AUTOSAR XML (schema 4-3-0)
standard types defined: Boolean, UInt8, SInt8, UInt16, SInt16, UInt32, SInt32, boolean, uint8, sint8, uint16, sint16, uint32, sint32
package /Components
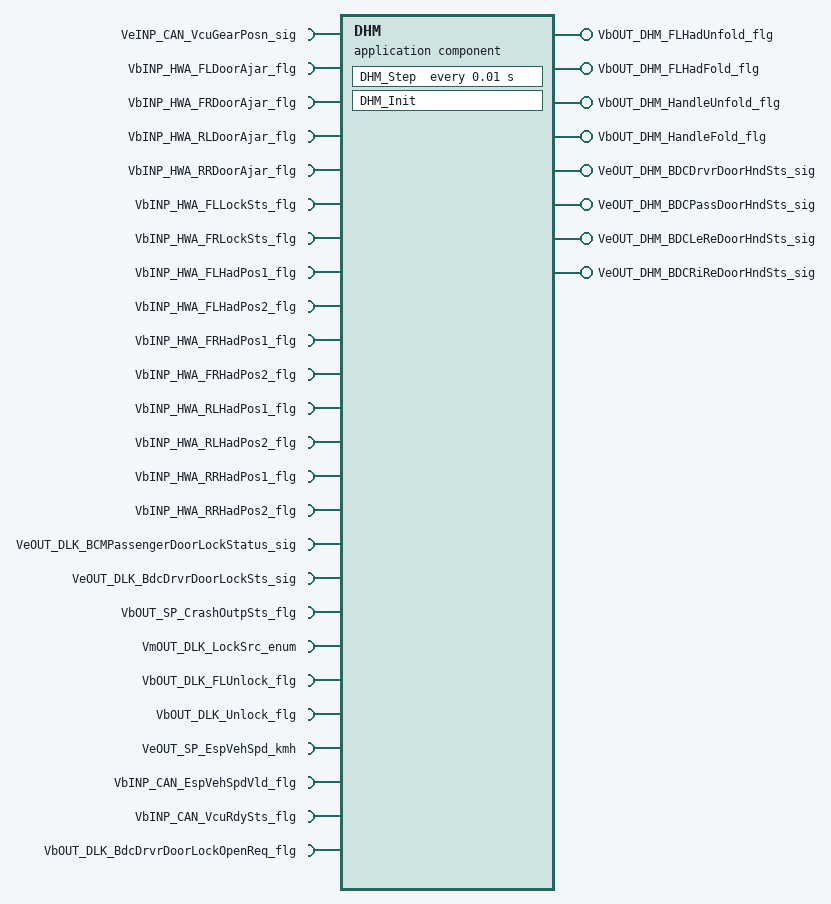
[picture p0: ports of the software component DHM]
  application sw component type DHM
    25 x require port:
      VeINP_CAN_VcuGearPosn_sig: nonqueued-receiver-com-spec{data-element=VeINP_CAN_VcuGearPosn_sig, init-value=0}, required-interface=VeINP_CAN_VcuGearPosn_sig
      VbINP_HWA_FLDoorAjar_flg: nonqueued-receiver-com-spec{data-element=VbINP_HWA_FLDoorAjar_flg, init-value=0}, required-interface=VbINP_HWA_FLDoorAjar_flg
      VbINP_HWA_FRDoorAjar_flg: nonqueued-receiver-com-spec{data-element=VbINP_HWA_FRDoorAjar_flg, init-value=0}, required-interface=VbINP_HWA_FRDoorAjar_flg
      VbINP_HWA_RLDoorAjar_flg: nonqueued-receiver-com-spec{data-element=VbINP_HWA_RLDoorAjar_flg, init-value=0}, required-interface=VbINP_HWA_RLDoorAjar_flg
      VbINP_HWA_RRDoorAjar_flg: nonqueued-receiver-com-spec{data-element=VbINP_HWA_RRDoorAjar_flg, init-value=0}, required-interface=VbINP_HWA_RRDoorAjar_flg
      VbINP_HWA_FLLockSts_flg: nonqueued-receiver-com-spec{data-element=VbINP_HWA_FLLockSts_flg, init-value=0}, required-interface=VbINP_HWA_FLLockSts_flg
      VbINP_HWA_FRLockSts_flg: nonqueued-receiver-com-spec{data-element=VbINP_HWA_FRLockSts_flg, init-value=0}, required-interface=VbINP_HWA_FRLockSts_flg
      VbINP_HWA_FLHadPos1_flg: nonqueued-receiver-com-spec{data-element=VbINP_HWA_FLHadPos1_flg, init-value=0}, required-interface=VbINP_HWA_FLHadPos1_flg
      VbINP_HWA_FLHadPos2_flg: nonqueued-receiver-com-spec{data-element=VbINP_HWA_FLHadPos2_flg, init-value=0}, required-interface=VbINP_HWA_FLHadPos2_flg
      VbINP_HWA_FRHadPos1_flg: nonqueued-receiver-com-spec{data-element=VbINP_HWA_FRHadPos1_flg, init-value=0}, required-interface=VbINP_HWA_FRHadPos1_flg
      VbINP_HWA_FRHadPos2_flg: nonqueued-receiver-com-spec{data-element=VbINP_HWA_FRHadPos2_flg, init-value=0}, required-interface=VbINP_HWA_FRHadPos2_flg
      VbINP_HWA_RLHadPos1_flg: nonqueued-receiver-com-spec{data-element=VbINP_HWA_RLHadPos1_flg, init-value=0}, required-interface=VbINP_HWA_RLHadPos1_flg
      VbINP_HWA_RLHadPos2_flg: nonqueued-receiver-com-spec{data-element=VbINP_HWA_RLHadPos2_flg, init-value=0}, required-interface=VbINP_HWA_RLHadPos2_flg
      VbINP_HWA_RRHadPos1_flg: nonqueued-receiver-com-spec{data-element=VbINP_HWA_RRHadPos1_flg, init-value=0}, required-interface=VbINP_HWA_RRHadPos1_flg
      VbINP_HWA_RRHadPos2_flg: nonqueued-receiver-com-spec{data-element=VbINP_HWA_RRHadPos2_flg, init-value=0}, required-interface=VbINP_HWA_RRHadPos2_flg
      VeOUT_DLK_BCMPassengerDoorLockStatus_sig: nonqueued-receiver-com-spec{data-element=VeOUT_DLK_BCMPassengerDoorLockStatus_sig, init-value=0}, required-interface=VeOUT_DLK_BCMPassengerDoorLockStatus_sig
      VeOUT_DLK_BdcDrvrDoorLockSts_sig: nonqueued-receiver-com-spec{data-element=VeOUT_DLK_BdcDrvrDoorLockSts_sig, init-value=0}, required-interface=VeOUT_DLK_BdcDrvrDoorLockSts_sig
      VbOUT_SP_CrashOutpSts_flg: nonqueued-receiver-com-spec{data-element=VbOUT_SP_CrashOutpSts_flg, init-value=0}, required-interface=VbOUT_SP_CrashOutpSts_flg
      VmOUT_DLK_LockSrc_enum: nonqueued-receiver-com-spec{data-element=VmOUT_DLK_LockSrc_enum, init-value=0}, required-interface=VmOUT_DLK_LockSrc_enum
      VbOUT_DLK_FLUnlock_flg: nonqueued-receiver-com-spec{data-element=VbOUT_DLK_FLUnlock_flg, init-value=0}, required-interface=VbOUT_DLK_FLUnlock_flg
      VbOUT_DLK_Unlock_flg: nonqueued-receiver-com-spec{data-element=VbOUT_DLK_Unlock_flg, init-value=0}, required-interface=VbOUT_DLK_Unlock_flg
      VeOUT_SP_EspVehSpd_kmh: nonqueued-receiver-com-spec{data-element=VeOUT_SP_EspVehSpd_kmh, init-value=0}, required-interface=VeOUT_SP_EspVehSpd_kmh
      VbINP_CAN_EspVehSpdVld_flg: nonqueued-receiver-com-spec{data-element=VbINP_CAN_EspVehSpdVld_flg, init-value=0}, required-interface=VbINP_CAN_EspVehSpdVld_flg
      VbINP_CAN_VcuRdySts_flg: nonqueued-receiver-com-spec{data-element=VbINP_CAN_VcuRdySts_flg, init-value=0}, required-interface=VbINP_CAN_VcuRdySts_flg
      VbOUT_DLK_BdcDrvrDoorLockOpenReq_flg: nonqueued-receiver-com-spec{data-element=VbOUT_DLK_BdcDrvrDoorLockOpenReq_flg, init-value=0}, required-interface=VbOUT_DLK_BdcDrvrDoorLockOpenReq_flg
    8 x provide port:
      VbOUT_DHM_FLHadUnfold_flg: nonqueued-sender-com-spec{data-element=VbOUT_DHM_FLHadUnfold_flg, init-value=0}, provided-interface=VbOUT_DHM_FLHadUnfold_flg
      VbOUT_DHM_FLHadFold_flg: nonqueued-sender-com-spec{data-element=VbOUT_DHM_FLHadFold_flg, init-value=0}, provided-interface=VbOUT_DHM_FLHadFold_flg
      VbOUT_DHM_HandleUnfold_flg: nonqueued-sender-com-spec{data-element=VbOUT_DHM_HandleUnfold_flg, init-value=0}, provided-interface=VbOUT_DHM_HandleUnfold_flg
      VbOUT_DHM_HandleFold_flg: nonqueued-sender-com-spec{data-element=VbOUT_DHM_HandleFold_flg, init-value=0}, provided-interface=VbOUT_DHM_HandleFold_flg
      VeOUT_DHM_BDCDrvrDoorHndSts_sig: nonqueued-sender-com-spec{data-element=VeOUT_DHM_BDCDrvrDoorHndSts_sig, init-value=0}, provided-interface=VeOUT_DHM_BDCDrvrDoorHndSts_sig
      VeOUT_DHM_BDCPassDoorHndSts_sig: nonqueued-sender-com-spec{data-element=VeOUT_DHM_BDCPassDoorHndSts_sig, init-value=0}, provided-interface=VeOUT_DHM_BDCPassDoorHndSts_sig
      VeOUT_DHM_BDCLeReDoorHndSts_sig: nonqueued-sender-com-spec{data-element=VeOUT_DHM_BDCLeReDoorHndSts_sig, init-value=0}, provided-interface=VeOUT_DHM_BDCLeReDoorHndSts_sig
      VeOUT_DHM_BDCRiReDoorHndSts_sig: nonqueued-sender-com-spec{data-element=VeOUT_DHM_BDCRiReDoorHndSts_sig, init-value=0}, provided-interface=VeOUT_DHM_BDCRiReDoorHndSts_sig
    behavior DHM: data-type-mapping=DataTypeMappingsSet, handle-termination-and-restart=NO-SUPPORT
      init event DHM_InitEvent: start-on-event=DHM_Init
      timing event Event_Runnable_Step: start-on-event=DHM_Step, period=0.01
      runnable DHM_Init
      runnable DHM_Step
        data-receive-point-by-arguments:
          25 x access:
            IN_VeINP_CAN_VcuGearPosn_sig_VeINP_CAN_VcuGearPosn_sig: accessed-variable=VeINP_CAN_VcuGearPosn_sig.VeINP_CAN_VcuGearPosn_sig
            IN_VbINP_HWA_FLDoorAjar_flg_VbINP_HWA_FLDoorAjar_flg: accessed-variable=VbINP_HWA_FLDoorAjar_flg.VbINP_HWA_FLDoorAjar_flg
            IN_VbINP_HWA_FRDoorAjar_flg_VbINP_HWA_FRDoorAjar_flg: accessed-variable=VbINP_HWA_FRDoorAjar_flg.VbINP_HWA_FRDoorAjar_flg
            IN_VbINP_HWA_RLDoorAjar_flg_VbINP_HWA_RLDoorAjar_flg: accessed-variable=VbINP_HWA_RLDoorAjar_flg.VbINP_HWA_RLDoorAjar_flg
            IN_VbINP_HWA_RRDoorAjar_flg_VbINP_HWA_RRDoorAjar_flg: accessed-variable=VbINP_HWA_RRDoorAjar_flg.VbINP_HWA_RRDoorAjar_flg
            IN_VbINP_HWA_FLLockSts_flg_VbINP_HWA_FLLockSts_flg: accessed-variable=VbINP_HWA_FLLockSts_flg.VbINP_HWA_FLLockSts_flg
            IN_VbINP_HWA_FRLockSts_flg_VbINP_HWA_FRLockSts_flg: accessed-variable=VbINP_HWA_FRLockSts_flg.VbINP_HWA_FRLockSts_flg
            IN_VbINP_HWA_FLHadPos1_flg_VbINP_HWA_FLHadPos1_flg: accessed-variable=VbINP_HWA_FLHadPos1_flg.VbINP_HWA_FLHadPos1_flg
            IN_VbINP_HWA_FLHadPos2_flg_VbINP_HWA_FLHadPos2_flg: accessed-variable=VbINP_HWA_FLHadPos2_flg.VbINP_HWA_FLHadPos2_flg
            IN_VbINP_HWA_FRHadPos1_flg_VbINP_HWA_FRHadPos1_flg: accessed-variable=VbINP_HWA_FRHadPos1_flg.VbINP_HWA_FRHadPos1_flg
            IN_VbINP_HWA_FRHadPos2_flg_VbINP_HWA_FRHadPos2_flg: accessed-variable=VbINP_HWA_FRHadPos2_flg.VbINP_HWA_FRHadPos2_flg
            IN_VbINP_HWA_RLHadPos1_flg_VbINP_HWA_RLHadPos1_flg: accessed-variable=VbINP_HWA_RLHadPos1_flg.VbINP_HWA_RLHadPos1_flg
            IN_VbINP_HWA_RLHadPos2_flg_VbINP_HWA_RLHadPos2_flg: accessed-variable=VbINP_HWA_RLHadPos2_flg.VbINP_HWA_RLHadPos2_flg
            IN_VbINP_HWA_RRHadPos1_flg_VbINP_HWA_RRHadPos1_flg: accessed-variable=VbINP_HWA_RRHadPos1_flg.VbINP_HWA_RRHadPos1_flg
            IN_VbINP_HWA_RRHadPos2_flg_VbINP_HWA_RRHadPos2_flg: accessed-variable=VbINP_HWA_RRHadPos2_flg.VbINP_HWA_RRHadPos2_flg
            IN_VeOUT_DLK_BCMPassengerDoorLockStatus_sig_VeOUT_DLK_BCMPassengerDoorLockStatus_sig: accessed-variable=VeOUT_DLK_BCMPassengerDoorLockStatus_sig.VeOUT_DLK_BCMPassengerDoorLockStatus_sig
            IN_VeOUT_DLK_BdcDrvrDoorLockSts_sig_VeOUT_DLK_BdcDrvrDoorLockSts_sig: accessed-variable=VeOUT_DLK_BdcDrvrDoorLockSts_sig.VeOUT_DLK_BdcDrvrDoorLockSts_sig
            IN_VbOUT_SP_CrashOutpSts_flg_VbOUT_SP_CrashOutpSts_flg: accessed-variable=VbOUT_SP_CrashOutpSts_flg.VbOUT_SP_CrashOutpSts_flg
            IN_VmOUT_DLK_LockSrc_enum_VmOUT_DLK_LockSrc_enum: accessed-variable=VmOUT_DLK_LockSrc_enum.VmOUT_DLK_LockSrc_enum
            IN_VbOUT_DLK_FLUnlock_flg_VbOUT_DLK_FLUnlock_flg: accessed-variable=VbOUT_DLK_FLUnlock_flg.VbOUT_DLK_FLUnlock_flg
            IN_VbOUT_DLK_Unlock_flg_VbOUT_DLK_Unlock_flg: accessed-variable=VbOUT_DLK_Unlock_flg.VbOUT_DLK_Unlock_flg
            IN_VeOUT_SP_EspVehSpd_kmh_VeOUT_SP_EspVehSpd_kmh: accessed-variable=VeOUT_SP_EspVehSpd_kmh.VeOUT_SP_EspVehSpd_kmh
            IN_VbINP_CAN_EspVehSpdVld_flg_VbINP_CAN_EspVehSpdVld_flg: accessed-variable=VbINP_CAN_EspVehSpdVld_flg.VbINP_CAN_EspVehSpdVld_flg
            IN_VbINP_CAN_VcuRdySts_flg_VbINP_CAN_VcuRdySts_flg: accessed-variable=VbINP_CAN_VcuRdySts_flg.VbINP_CAN_VcuRdySts_flg
            IN_VbOUT_DLK_BdcDrvrDoorLockOpenReq_flg_VbOUT_DLK_BdcDrvrDoorLockOpenReq_flg: accessed-variable=VbOUT_DLK_BdcDrvrDoorLockOpenReq_flg.VbOUT_DLK_BdcDrvrDoorLockOpenReq_flg
        data-send-points:
          8 x access:
            OUT_VbOUT_DHM_FLHadUnfold_flg_VbOUT_DHM_FLHadUnfold_flg: accessed-variable=VbOUT_DHM_FLHadUnfold_flg.VbOUT_DHM_FLHadUnfold_flg
            OUT_VbOUT_DHM_FLHadFold_flg_VbOUT_DHM_FLHadFold_flg: accessed-variable=VbOUT_DHM_FLHadFold_flg.VbOUT_DHM_FLHadFold_flg
            OUT_VbOUT_DHM_HandleUnfold_flg_VbOUT_DHM_HandleUnfold_flg: accessed-variable=VbOUT_DHM_HandleUnfold_flg.VbOUT_DHM_HandleUnfold_flg
            OUT_VbOUT_DHM_HandleFold_flg_VbOUT_DHM_HandleFold_flg: accessed-variable=VbOUT_DHM_HandleFold_flg.VbOUT_DHM_HandleFold_flg
            OUT_VeOUT_DHM_BDCDrvrDoorHndSts_sig_VeOUT_DHM_BDCDrvrDoorHndSts_sig: accessed-variable=VeOUT_DHM_BDCDrvrDoorHndSts_sig.VeOUT_DHM_BDCDrvrDoorHndSts_sig
            OUT_VeOUT_DHM_BDCPassDoorHndSts_sig_VeOUT_DHM_BDCPassDoorHndSts_sig: accessed-variable=VeOUT_DHM_BDCPassDoorHndSts_sig.VeOUT_DHM_BDCPassDoorHndSts_sig
            OUT_VeOUT_DHM_BDCLeReDoorHndSts_sig_VeOUT_DHM_BDCLeReDoorHndSts_sig: accessed-variable=VeOUT_DHM_BDCLeReDoorHndSts_sig.VeOUT_DHM_BDCLeReDoorHndSts_sig
            OUT_VeOUT_DHM_BDCRiReDoorHndSts_sig_VeOUT_DHM_BDCRiReDoorHndSts_sig: accessed-variable=VeOUT_DHM_BDCRiReDoorHndSts_sig.VeOUT_DHM_BDCRiReDoorHndSts_sig
package /Interfaces
  33 x sender receiver interface:
    VeINP_CAN_VcuGearPosn_sig
      data VeINP_CAN_VcuGearPosn_sig: category=VALUE, sw-calibration-access=READ-ONLY, type=UInt8
    VbINP_HWA_FLDoorAjar_flg
      data VbINP_HWA_FLDoorAjar_flg: category=BOOLEAN, sw-calibration-access=READ-ONLY, type=Boolean
    VbINP_HWA_FRDoorAjar_flg
      data VbINP_HWA_FRDoorAjar_flg: category=BOOLEAN, sw-calibration-access=READ-ONLY, type=Boolean
    VbINP_HWA_RLDoorAjar_flg
      data VbINP_HWA_RLDoorAjar_flg: category=BOOLEAN, sw-calibration-access=READ-ONLY, type=Boolean
    VbINP_HWA_RRDoorAjar_flg
      data VbINP_HWA_RRDoorAjar_flg: category=BOOLEAN, sw-calibration-access=READ-ONLY, type=Boolean
    VbINP_HWA_FLLockSts_flg
      data VbINP_HWA_FLLockSts_flg: category=BOOLEAN, sw-calibration-access=READ-ONLY, type=Boolean
    VbINP_HWA_FRLockSts_flg
      data VbINP_HWA_FRLockSts_flg: category=BOOLEAN, sw-calibration-access=READ-ONLY, type=Boolean
    VbINP_HWA_FLHadPos1_flg
      data VbINP_HWA_FLHadPos1_flg: category=BOOLEAN, sw-calibration-access=READ-ONLY, type=Boolean
    VbINP_HWA_FLHadPos2_flg
      data VbINP_HWA_FLHadPos2_flg: category=BOOLEAN, sw-calibration-access=READ-ONLY, type=Boolean
    VbINP_HWA_FRHadPos1_flg
      data VbINP_HWA_FRHadPos1_flg: category=BOOLEAN, sw-calibration-access=READ-ONLY, type=Boolean
    VbINP_HWA_FRHadPos2_flg
      data VbINP_HWA_FRHadPos2_flg: category=BOOLEAN, sw-calibration-access=READ-ONLY, type=Boolean
    VbINP_HWA_RLHadPos1_flg
      data VbINP_HWA_RLHadPos1_flg: category=BOOLEAN, sw-calibration-access=READ-ONLY, type=Boolean
    VbINP_HWA_RLHadPos2_flg
      data VbINP_HWA_RLHadPos2_flg: category=BOOLEAN, sw-calibration-access=READ-ONLY, type=Boolean
    VbINP_HWA_RRHadPos1_flg
      data VbINP_HWA_RRHadPos1_flg: category=BOOLEAN, sw-calibration-access=READ-ONLY, type=Boolean
    VbINP_HWA_RRHadPos2_flg
      data VbINP_HWA_RRHadPos2_flg: category=BOOLEAN, sw-calibration-access=READ-ONLY, type=Boolean
    VeOUT_DLK_BCMPassengerDoorLockStatus_sig
      data VeOUT_DLK_BCMPassengerDoorLockStatus_sig: category=VALUE, sw-calibration-access=READ-ONLY, type=UInt8
    VeOUT_DLK_BdcDrvrDoorLockSts_sig
      data VeOUT_DLK_BdcDrvrDoorLockSts_sig: category=VALUE, sw-calibration-access=READ-ONLY, type=UInt8
    VbOUT_SP_CrashOutpSts_flg
      data VbOUT_SP_CrashOutpSts_flg: category=BOOLEAN, sw-calibration-access=READ-ONLY, type=Boolean
    VmOUT_DLK_LockSrc_enum
      data VmOUT_DLK_LockSrc_enum: category=VALUE, sw-calibration-access=READ-ONLY, type=UInt8
    VbOUT_DLK_FLUnlock_flg
      data VbOUT_DLK_FLUnlock_flg: category=BOOLEAN, sw-calibration-access=READ-ONLY, type=Boolean
    VbOUT_DLK_Unlock_flg
      data VbOUT_DLK_Unlock_flg: category=BOOLEAN, sw-calibration-access=READ-ONLY, type=Boolean
    VeOUT_SP_EspVehSpd_kmh
      data VeOUT_SP_EspVehSpd_kmh: category=VALUE, sw-calibration-access=READ-ONLY, type=UInt8
    VbINP_CAN_EspVehSpdVld_flg
      data VbINP_CAN_EspVehSpdVld_flg: category=BOOLEAN, sw-calibration-access=READ-ONLY, type=Boolean
    VbINP_CAN_VcuRdySts_flg
      data VbINP_CAN_VcuRdySts_flg: category=BOOLEAN, sw-calibration-access=READ-ONLY, type=Boolean
    VbOUT_DLK_BdcDrvrDoorLockOpenReq_flg
      data VbOUT_DLK_BdcDrvrDoorLockOpenReq_flg: category=BOOLEAN, sw-calibration-access=READ-ONLY, type=Boolean
    VbOUT_DHM_FLHadUnfold_flg
      data VbOUT_DHM_FLHadUnfold_flg: category=BOOLEAN, sw-calibration-access=READ-ONLY, type=Boolean
    VbOUT_DHM_FLHadFold_flg
      data VbOUT_DHM_FLHadFold_flg: category=BOOLEAN, sw-calibration-access=READ-ONLY, type=Boolean
    VbOUT_DHM_HandleUnfold_flg
      data VbOUT_DHM_HandleUnfold_flg: category=BOOLEAN, sw-calibration-access=READ-ONLY, type=Boolean
    VbOUT_DHM_HandleFold_flg
      data VbOUT_DHM_HandleFold_flg: category=BOOLEAN, sw-calibration-access=READ-ONLY, type=Boolean
    VeOUT_DHM_BDCDrvrDoorHndSts_sig
      data VeOUT_DHM_BDCDrvrDoorHndSts_sig: category=VALUE, sw-calibration-access=READ-ONLY, type=UInt8
    VeOUT_DHM_BDCPassDoorHndSts_sig
      data VeOUT_DHM_BDCPassDoorHndSts_sig: category=VALUE, sw-calibration-access=READ-ONLY, type=UInt8
    VeOUT_DHM_BDCLeReDoorHndSts_sig
      data VeOUT_DHM_BDCLeReDoorHndSts_sig: category=VALUE, sw-calibration-access=READ-ONLY, type=UInt8
    VeOUT_DHM_BDCRiReDoorHndSts_sig
      data VeOUT_DHM_BDCRiReDoorHndSts_sig: category=VALUE, sw-calibration-access=READ-ONLY, type=UInt8
package /DHM_imp
  swc implementation DHM: behavior=DHM
    code-descriptors:
      code Default: artifact-descriptors=autosar-engineering-object={short-label=Default, category=SWSRC}
package /DataTypes/SwAddrMethods
  sw addr method CODE: section-type=CODE
  sw addr method CONST: section-type=CONST
  sw addr method VAR: section-type=VAR
package /DataTypes/ApplicationDataTypes
  7 x app type, all with sw-calibration-access=READ-WRITE:
    Boolean: category=BOOLEAN, compu {0=FALSE, 1=TRUE}
    UInt8: category=VALUE, compu {identical}, range phys 0..255
    SInt8: category=VALUE, compu {identical}, range phys -128..127
    UInt16: category=VALUE, compu {identical}, range phys 0..65535
    SInt16: category=VALUE, compu {identical}, range phys -32768..32767
    UInt32: category=VALUE, compu {identical}, range phys 0..4294967295
    SInt32: category=VALUE, compu {identical}, range phys -2147483648..2147483647
  application record data type TURN_DIAG_STRUCT: category=STRUCTURE, sw-calibration-access=READ-WRITE
    5 x application record element:
      OpenLoad: category=BOOLEAN, type=Boolean
      Overload: category=BOOLEAN, type=Boolean
      NormA2D: category=VALUE, type=UInt8
      Turn_LTH: category=VALUE, type=UInt8
      TurnCalib_th: category=VALUE, type=UInt8
  application array data type rt_Array_UInt8_8: category=ARRAY, sw-calibration-access=READ-WRITE
    element rt_Array_UInt8_8: category=VALUE, type=UInt8, array-size-semantics=FIXED-SIZE, max-number-of-elements=8
  application array data type rt_Array_UInt8_20: category=ARRAY, sw-calibration-access=READ-WRITE
    element rt_Array_UInt8_20: category=VALUE, type=UInt8, array-size-semantics=FIXED-SIZE, max-number-of-elements=20
package /DataTypes/ApplicationDataTypes/DataConstrs
  range DC_TURN_DIAG_STRUCT: phys 0
package /DataTypes/ImplementationDataTypes
  impl type TURN_DIAG_STRUCT: category=STRUCTURE
    5 x element, all with category=TYPE_REFERENCE:
      OpenLoad: implementation-data-type=Boolean
      Overload: implementation-data-type=Boolean
      NormA2D: implementation-data-type=UInt8
      Turn_LTH: implementation-data-type=UInt8
      TurnCalib_th: implementation-data-type=UInt8
  impl type rt_Array_UInt8_8: category=ARRAY
    element rt_Array_UInt8_8: array-size=8, array-size-semantics=FIXED-SIZE, implementation-data-type=UInt8
  impl type rt_Array_UInt8_20: category=ARRAY
    element rt_Array_UInt8_20: array-size=20, array-size-semantics=FIXED-SIZE, implementation-data-type=UInt8
package /DataTypes/Units
  unit NoUnit: factor-si-to-unit=1, offset-si-to-unit=0
package /DataTypes/DataTypeMappings
  data type mapping set DataTypeMappingsSet
    data-type-maps:
      application-data-type=Boolean, implementation-data-type=Boolean
      application-data-type=UInt8, implementation-data-type=UInt8
      application-data-type=SInt8, implementation-data-type=SInt8
      application-data-type=UInt16, implementation-data-type=UInt16
      application-data-type=SInt16, implementation-data-type=SInt16
      application-data-type=UInt32, implementation-data-type=UInt32
      application-data-type=SInt32, implementation-data-type=SInt32
      application-data-type=TURN_DIAG_STRUCT, implementation-data-type=TURN_DIAG_STRUCT
      application-data-type=rt_Array_UInt8_8, implementation-data-type=rt_Array_UInt8_8
      application-data-type=rt_Array_UInt8_20, implementation-data-type=rt_Array_UInt8_20
